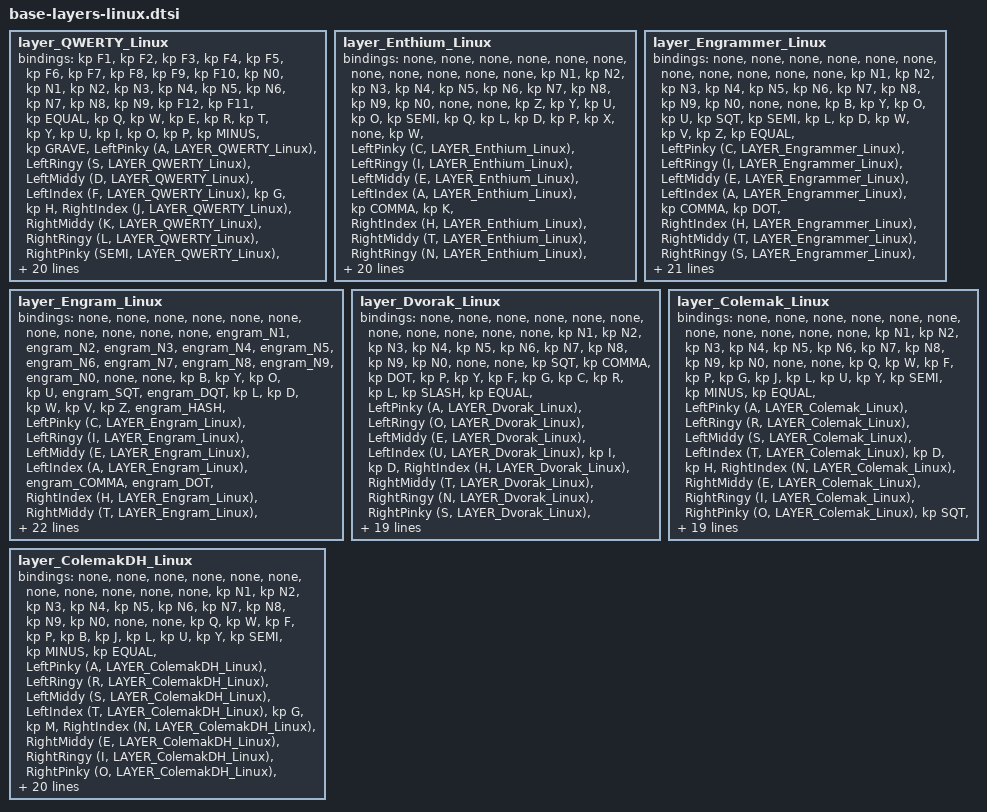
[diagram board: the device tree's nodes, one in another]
/*
 * Linux Base Layers (Layers 32-38)
 *
 * This file contains Linux-specific versions of the base keyboard layouts.
 * These are duplicates of layers 0-6 but exist in the layer 32-38 range
 * to allow seamless switching between macOS and Linux configurations.
 */

        layer_QWERTY_Linux {
            bindings = <
               &kp F1                              &kp F2                              &kp F3                              &kp F4                              &kp F5                                                                                                                                                                                                                   &kp F6                               &kp F7                               &kp F8                                 &kp F9               &kp F10
               &kp N0                              &kp N1                              &kp N2                              &kp N3                              &kp N4  &kp N5                                                                                                                                                                            &kp N6                               &kp N7                               &kp N8                               &kp N9                                 &kp F12               &kp F11
            &kp EQUAL                               &kp Q                               &kp W                               &kp E                               &kp R   &kp T                                                                                                                                                                             &kp Y                                &kp U                                &kp I                                &kp O                                  &kp P             &kp MINUS
            &kp GRAVE  &LeftPinky (A, LAYER_QWERTY_Linux)  &LeftRingy (S, LAYER_QWERTY_Linux)  &LeftMiddy (D, LAYER_QWERTY_Linux)  &LeftIndex (F, LAYER_QWERTY_Linux)   &kp G                                                                                                                                                                             &kp H  &RightIndex (J, LAYER_QWERTY_Linux)  &RightMiddy (K, LAYER_QWERTY_Linux)  &RightRingy (L, LAYER_QWERTY_Linux)  &RightPinky (SEMI, LAYER_QWERTY_Linux)               &kp SQT
      &mo LAYER_Lower_Linux                               &kp Z                               &kp X                               &kp C                               &kp V   &kp B      &thumb LAYER_Function_Linux ESC                &parang_left               &parang_right         &kp _HOME                &kp _END  &thumb LAYER_System_Linux ENTER   &kp N                                &kp M                            &kp COMMA                              &kp DOT                               &kp FSLH       &mo LAYER_Lower_Linux
 &magic LAYER_Magic_Linux 0                           &kp GRAVE                            &kp LBKT                            &kp RBKT       &thumb LAYER_Emoji_Linux BSLH          &thumb LAYER_Cursor_Linux BACKSPACE  &thumb LAYER_Number_Linux DELETE  &thumb LAYER_Typing_Linux INSERT  &mo LAYER_Typing_Linux  &thumb LAYER_Mouse_Linux TAB  &space LAYER_Symbol_Linux SPACE             &thumb LAYER_World_Linux PAGE_UP                 &td_scroll_up_linux               &td_scroll_down_linux                               &lt LAYER_MouseWarp_Linux PG_DN  &magic LAYER_Magic_Linux 0
            >;
        };

        layer_Enthium_Linux {
            bindings = <
                &none                                &none                                &none                                &none                                &none                                                                                                                                                                                                                         &none                                 &none                                 &none                                 &none                 &none
                &none                               &kp N1                               &kp N2                               &kp N3                               &kp N4     &kp N5                                                                                                                                                                             &kp N6                                &kp N7                                &kp N8                                &kp N9                                &kp N0                 &none
                &none                                &kp Z                                &kp Y                                &kp U                                &kp O   &kp SEMI                                                                                                                                                                              &kp Q                                 &kp L                                 &kp D                                 &kp P                                 &kp X                 &none
                &kp W  &LeftPinky (C, LAYER_Enthium_Linux)  &LeftRingy (I, LAYER_Enthium_Linux)  &LeftMiddy (E, LAYER_Enthium_Linux)  &LeftIndex (A, LAYER_Enthium_Linux)  &kp COMMA                                                                                                                                                                              &kp K  &RightIndex (H, LAYER_Enthium_Linux)  &RightMiddy (T, LAYER_Enthium_Linux)  &RightRingy (N, LAYER_Enthium_Linux)  &RightPinky (S, LAYER_Enthium_Linux)                 &kp F
      &mo LAYER_Lower_Linux                              &kp SQT                            &kp MINUS                            &kp EQUAL                              &kp DOT   &kp FSLH  &thumb LAYER_Function_Linux ESC             &parang_left               &parang_right                   &kp _HOME                      &kp _END  &thumb LAYER_System_Linux ENTER   &kp J                                 &kp M                                 &kp G                                 &kp B                                 &kp V       &mo LAYER_Lower_Linux
 &magic LAYER_Magic_Linux 0                            &kp GRAVE                             &kp LBKT                             &kp RBKT        &thumb LAYER_Emoji_Linux BSLH             &thumb LAYER_Cursor_Linux SPACE  &thumb LAYER_Number_Linux TAB  &thumb LAYER_Typing_Linux INSERT  &thumb LAYER_Typing_Linux DELETE  &thumb LAYER_Mouse_Linux BACKSPACE      &space LAYER_Symbol_Linux R              &thumb LAYER_World_Linux PAGE_UP                  &td_scroll_up_linux                &td_scroll_down_linux                             &lt LAYER_MouseWarp_Linux PG_DN  &magic LAYER_Magic_Linux 0
            >;
        };

        layer_Engrammer_Linux {
            bindings = <
                &none                                  &none                                  &none                                  &none                                  &none                                                                                                                                                                                                                    &none                                   &none                                   &none                                   &none                 &none
                &none                                 &kp N1                                 &kp N2                                 &kp N3                                 &kp N4     &kp N5                                                                                                                                                                      &kp N6                                  &kp N7                                  &kp N8                                  &kp N9                                  &kp N0                 &none
                &none                                  &kp B                                  &kp Y                                  &kp O                                  &kp U    &kp SQT                                                                                                                                                                    &kp SEMI                                   &kp L                                   &kp D                                   &kp W                                   &kp V                 &kp Z
            &kp EQUAL  &LeftPinky (C, LAYER_Engrammer_Linux)  &LeftRingy (I, LAYER_Engrammer_Linux)  &LeftMiddy (E, LAYER_Engrammer_Linux)  &LeftIndex (A, LAYER_Engrammer_Linux)  &kp COMMA                                                                                                                                                                     &kp DOT  &RightIndex (H, LAYER_Engrammer_Linux)  &RightMiddy (T, LAYER_Engrammer_Linux)  &RightRingy (S, LAYER_Engrammer_Linux)  &RightPinky (N, LAYER_Engrammer_Linux)                 &kp Q
      &mo LAYER_Lower_Linux                                  &kp G                                  &kp X                                  &kp J                                  &kp K  &kp MINUS      &thumb LAYER_Function_Linux ESC                &parang_left               &parang_right         &kp _HOME                &kp _END  &thumb LAYER_System_Linux ENTER  &kp FSLH                                   &kp R                                   &kp M                                   &kp F                                   &kp P       &mo LAYER_Lower_Linux
 &magic LAYER_Magic_Linux 0                              &kp GRAVE                               &kp LBKT                               &kp RBKT          &thumb LAYER_Emoji_Linux BSLH             &thumb LAYER_Cursor_Linux BACKSPACE  &thumb LAYER_Number_Linux DELETE  &thumb LAYER_Typing_Linux INSERT  &mo LAYER_Typing_Linux  &thumb LAYER_Mouse_Linux TAB  &space LAYER_Symbol_Linux SPACE                    &thumb LAYER_World_Linux PAGE_UP                    &td_scroll_up_linux                  &td_scroll_down_linux                               &lt LAYER_MouseWarp_Linux PG_DN  &magic LAYER_Magic_Linux 0
            >;
        };

        layer_Engram_Linux {
            bindings = <
                &none                               &none                               &none                               &none                                 &none                                                                                                                                                                                                                          &none                                &none                                &none                                &none                 &none
                &none                          &engram_N1                          &engram_N2                          &engram_N3                            &engram_N4     &engram_N5                                                                                                                                                                       &engram_N6                           &engram_N7                           &engram_N8                           &engram_N9                           &engram_N0                 &none
                &none                               &kp B                               &kp Y                               &kp O                                 &kp U    &engram_SQT                                                                                                                                                                      &engram_DQT                                &kp L                                &kp D                                &kp W                                &kp V                 &kp Z
         &engram_HASH  &LeftPinky (C, LAYER_Engram_Linux)  &LeftRingy (I, LAYER_Engram_Linux)  &LeftMiddy (E, LAYER_Engram_Linux)      &LeftIndex (A, LAYER_Engram_Linux)  &engram_COMMA                                                                                                                                                                      &engram_DOT  &RightIndex (H, LAYER_Engram_Linux)  &RightMiddy (T, LAYER_Engram_Linux)  &RightRingy (S, LAYER_Engram_Linux)  &RightPinky (N, LAYER_Engram_Linux)                 &kp Q
      &mo LAYER_Lower_Linux                               &kp G                               &kp X                               &kp J                                 &kp K      &kp MINUS      &thumb LAYER_Function_Linux ESC                &parang_left               &parang_right         &kp _HOME                &kp _END  &thumb LAYER_System_Linux ENTER  &engram_QMARK                                &kp R                                &kp M                                &kp F                                &kp P       &mo LAYER_Lower_Linux
 &magic LAYER_Magic_Linux 0                        &engram_FSLH                            &kp LBKT                            &kp RBKT  &thumb_engram_AT LAYER_Emoji_Linux 0                 &thumb LAYER_Cursor_Linux BACKSPACE  &thumb LAYER_Number_Linux DELETE  &thumb LAYER_Typing_Linux INSERT  &mo LAYER_Typing_Linux  &thumb LAYER_Mouse_Linux TAB  &space LAYER_Symbol_Linux SPACE                      &thumb LAYER_World_Linux PAGE_UP                 &td_scroll_up_linux               &td_scroll_down_linux                            &lt LAYER_MouseWarp_Linux PG_DN  &magic LAYER_Magic_Linux 0
            >;
        };

        layer_Dvorak_Linux {
            bindings = <
                &none                               &none                               &none                               &none                               &none                                                                                                                                                                                                            &none                                &none                                &none                                &none                 &none
                &none                              &kp N1                              &kp N2                              &kp N3                              &kp N4  &kp N5                                                                                                                                                                    &kp N6                               &kp N7                               &kp N8                               &kp N9                               &kp N0                 &none
                &none                             &kp SQT                           &kp COMMA                             &kp DOT                               &kp P   &kp Y                                                                                                                                                                     &kp F                                &kp G                                &kp C                                &kp R                                &kp L             &kp SLASH
            &kp EQUAL  &LeftPinky (A, LAYER_Dvorak_Linux)  &LeftRingy (O, LAYER_Dvorak_Linux)  &LeftMiddy (E, LAYER_Dvorak_Linux)  &LeftIndex (U, LAYER_Dvorak_Linux)   &kp I                                                                                                                                                                     &kp D  &RightIndex (H, LAYER_Dvorak_Linux)  &RightMiddy (T, LAYER_Dvorak_Linux)  &RightRingy (N, LAYER_Dvorak_Linux)  &RightPinky (S, LAYER_Dvorak_Linux)             &kp MINUS
      &mo LAYER_Lower_Linux                            &kp SEMI                               &kp Q                               &kp J                               &kp K   &kp X      &thumb LAYER_Function_Linux ESC                &parang_left               &parang_right         &kp _HOME                &kp _END  &thumb LAYER_System_Linux ENTER   &kp B                                &kp M                                &kp W                                &kp V                                &kp Z       &mo LAYER_Lower_Linux
 &magic LAYER_Magic_Linux 0                           &kp GRAVE                            &kp LBKT                            &kp RBKT       &thumb LAYER_Emoji_Linux BSLH          &thumb LAYER_Cursor_Linux BACKSPACE  &thumb LAYER_Number_Linux DELETE  &thumb LAYER_Typing_Linux INSERT  &mo LAYER_Typing_Linux  &thumb LAYER_Mouse_Linux TAB  &space LAYER_Symbol_Linux SPACE             &thumb LAYER_World_Linux PAGE_UP                 &td_scroll_up_linux               &td_scroll_down_linux                            &lt LAYER_MouseWarp_Linux PG_DN  &magic LAYER_Magic_Linux 0
            >;
        };

        layer_Colemak_Linux {
            bindings = <
                &none                                &none                                &none                                &none                                &none                                                                                                                                                                                                             &none                                 &none                                 &none                                 &none                 &none
                &none                               &kp N1                               &kp N2                               &kp N3                               &kp N4  &kp N5                                                                                                                                                                    &kp N6                                &kp N7                                &kp N8                                &kp N9                                &kp N0                 &none
                &none                                &kp Q                                &kp W                                &kp F                                &kp P   &kp G                                                                                                                                                                     &kp J                                 &kp L                                 &kp U                                 &kp Y                              &kp SEMI             &kp MINUS
            &kp EQUAL  &LeftPinky (A, LAYER_Colemak_Linux)  &LeftRingy (R, LAYER_Colemak_Linux)  &LeftMiddy (S, LAYER_Colemak_Linux)  &LeftIndex (T, LAYER_Colemak_Linux)   &kp D                                                                                                                                                                     &kp H  &RightIndex (N, LAYER_Colemak_Linux)  &RightMiddy (E, LAYER_Colemak_Linux)  &RightRingy (I, LAYER_Colemak_Linux)  &RightPinky (O, LAYER_Colemak_Linux)               &kp SQT
      &mo LAYER_Lower_Linux                                &kp Z                                &kp X                                &kp C                                &kp V   &kp B      &thumb LAYER_Function_Linux ESC                &parang_left               &parang_right         &kp _HOME                &kp _END  &thumb LAYER_System_Linux ENTER   &kp K                                 &kp M                             &kp COMMA                               &kp DOT                              &kp FSLH       &mo LAYER_Lower_Linux
 &magic LAYER_Magic_Linux 0                            &kp GRAVE                             &kp LBKT                             &kp RBKT        &thumb LAYER_Emoji_Linux BSLH          &thumb LAYER_Cursor_Linux BACKSPACE  &thumb LAYER_Number_Linux DELETE  &crumb LAYER_Typing_Linux INSERT  &mo LAYER_Typing_Linux  &thumb LAYER_Mouse_Linux TAB  &space LAYER_Symbol_Linux SPACE              &thumb LAYER_World_Linux PAGE_UP                  &td_scroll_up_linux                &td_scroll_down_linux                             &lt LAYER_MouseWarp_Linux PG_DN  &magic LAYER_Magic_Linux 0
            >;
        };

        layer_ColemakDH_Linux {
            bindings = <
                &none                                  &none                                  &none                                  &none                                  &none                                                                                                                                                                                                               &none                                   &none                                   &none                                   &none                 &none
                &none                                 &kp N1                                 &kp N2                                 &kp N3                                 &kp N4  &kp N5                                                                                                                                                                    &kp N6                                  &kp N7                                  &kp N8                                  &kp N9                                  &kp N0                 &none
                &none                                  &kp Q                                  &kp W                                  &kp F                                  &kp P   &kp B                                                                                                                                                                     &kp J                                   &kp L                                   &kp U                                   &kp Y                                &kp SEMI             &kp MINUS
            &kp EQUAL  &LeftPinky (A, LAYER_ColemakDH_Linux)  &LeftRingy (R, LAYER_ColemakDH_Linux)  &LeftMiddy (S, LAYER_ColemakDH_Linux)  &LeftIndex (T, LAYER_ColemakDH_Linux)   &kp G                                                                                                                                                                     &kp M  &RightIndex (N, LAYER_ColemakDH_Linux)  &RightMiddy (E, LAYER_ColemakDH_Linux)  &RightRingy (I, LAYER_ColemakDH_Linux)  &RightPinky (O, LAYER_ColemakDH_Linux)               &kp SQT
      &mo LAYER_Lower_Linux                                  &kp Z                                  &kp X                                  &kp C                                  &kp D   &kp V      &thumb LAYER_Function_Linux ESC                &parang_left               &parang_right         &kp _HOME                &kp _END  &thumb LAYER_System_Linux ENTER   &kp K                                   &kp H                               &kp COMMA                                 &kp DOT                                &kp FSLH       &mo LAYER_Lower_Linux
 &magic LAYER_Magic_Linux 0                              &kp GRAVE                               &kp LBKT                               &kp RBKT          &thumb LAYER_Emoji_Linux BSLH          &thumb LAYER_Cursor_Linux BACKSPACE  &thumb LAYER_Number_Linux DELETE  &thumb LAYER_Typing_Linux INSERT  &mo LAYER_Typing_Linux  &thumb LAYER_Mouse_Linux TAB  &space LAYER_Symbol_Linux SPACE                &thumb LAYER_World_Linux PAGE_UP                    &td_scroll_up_linux                  &td_scroll_down_linux                               &lt LAYER_MouseWarp_Linux PG_DN  &magic LAYER_Magic_Linux 0
            >;
        };
